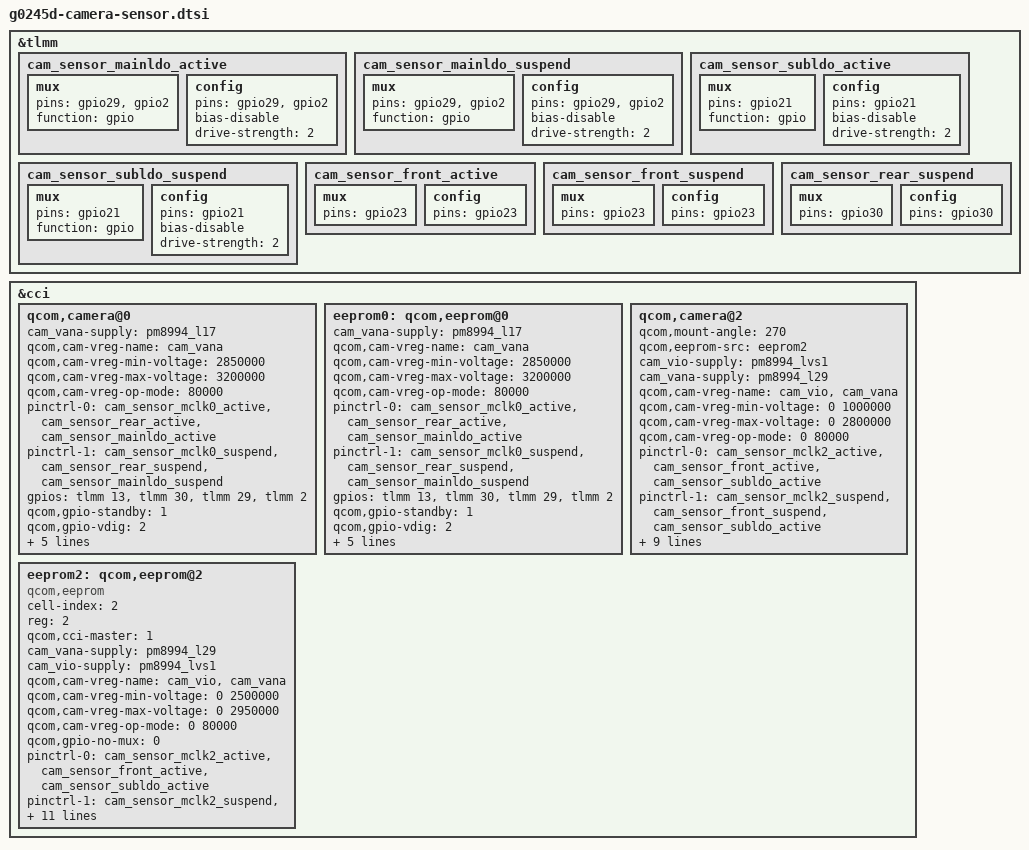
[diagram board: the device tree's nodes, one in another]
/*
 * G0245D camera sensor board topology (from the stock G0245D DTB).
 *
 * The board powers the camera modules through GPIO-switched rails, not
 * the MTP regulator set the donor msm8996-camera-sensor-mtp.dtsi uses:
 *   gpio29 = rear module main LDO enable (VDIG role)
 *   gpio2  = rear module VIO enable
 *   gpio21 = front module sub LDO enable (VDIG role)
 *
 * Sensor identity is resolved by the userspace probe path
 * (libmmcamera2_sensor_modules + /system/etc/camera/msm8996_camera.xml:
 * imx258 rear on CCI master 0, ov8856_cmb199 front on CCI master 1),
 * which drives the GPIO req-tbl and the vreg list taken verbatim from
 * the qcom,camera@N / qcom,eeprom@N nodes below. With the MTP config
 * the rails are never enabled and every CCI i2c read times out
 * (msm_cci_i2c_read rc -110), so the topology must match stock.
 *
 * Included after msm8996-camera-sensor-mtp.dtsi; nodes merge and the
 * properties here win.
 */

&tlmm {
	cam_sensor_mainldo_active: cam_sensor_mainldo_active {
		mux {
			pins = "gpio29", "gpio2";
			function = "gpio";
		};
		config {
			pins = "gpio29", "gpio2";
			bias-disable;
			drive-strength = <2>;
		};
	};

	cam_sensor_mainldo_suspend: cam_sensor_mainldo_suspend {
		mux {
			pins = "gpio29", "gpio2";
			function = "gpio";
		};
		config {
			pins = "gpio29", "gpio2";
			bias-disable;
			drive-strength = <2>;
		};
	};

	cam_sensor_subldo_active: cam_sensor_subldo_active {
		mux {
			pins = "gpio21";
			function = "gpio";
		};
		config {
			pins = "gpio21";
			bias-disable;
			drive-strength = <2>;
		};
	};

	cam_sensor_subldo_suspend: cam_sensor_subldo_suspend {
		mux {
			pins = "gpio21";
			function = "gpio";
		};
		config {
			pins = "gpio21";
			bias-disable;
			drive-strength = <2>;
		};
	};

	/* Stock groups drive only the standby pin; the donor set adds an
	 * extra gpio26 (front) / gpio29 (rear suspend) that stock does not
	 * touch. Pin lists merge by node name, so restate them here. */
	cam_sensor_front_active {
		mux {
			pins = "gpio23";
		};
		config {
			pins = "gpio23";
		};
	};

	cam_sensor_front_suspend {
		mux {
			pins = "gpio23";
		};
		config {
			pins = "gpio23";
		};
	};

	cam_sensor_rear_suspend {
		mux {
			pins = "gpio30";
		};
		config {
			pins = "gpio30";
		};
	};
};

&cci {
	/* The XML module list has no cell-index 1 camera; stock has no
	 * camera@1 / eeprom@1 either. Drop the MTP placeholders so nothing
	 * probes the wrong slot. */
	/delete-node/ qcom,camera@1;
	/delete-node/ qcom,eeprom@1;

	/* Rear: IMX258, CCI master 0, csiphy/csid 0. Vana is the only
	 * regulator; VDIG/VIO are gpio29/gpio2 via the req-tbl. */
	qcom,camera@0 {
		/delete-property/ qcom,ois-src;
		/delete-property/ cam_vdig-supply;
		/delete-property/ cam_vio-supply;
		/delete-property/ qcom,gpio-reset;
		/delete-property/ qcom,clock-rates;
		cam_vana-supply = <&pm8994_l17>;
		qcom,cam-vreg-name = "cam_vana";
		qcom,cam-vreg-min-voltage = <2850000>;
		qcom,cam-vreg-max-voltage = <3200000>;
		qcom,cam-vreg-op-mode = <80000>;
		pinctrl-0 = <&cam_sensor_mclk0_active
				&cam_sensor_rear_active
				&cam_sensor_mainldo_active>;
		pinctrl-1 = <&cam_sensor_mclk0_suspend
				&cam_sensor_rear_suspend
				&cam_sensor_mainldo_suspend>;
		gpios = <&tlmm 13 0>,
			<&tlmm 30 0>,
			<&tlmm 29 0>,
			<&tlmm 2 0>;
		qcom,gpio-standby = <1>;
		qcom,gpio-vdig = <2>;
		qcom,gpio-vio = <3>;
		qcom,gpio-req-tbl-num = <0 1 2 3>;
		qcom,gpio-req-tbl-flags = <1 0 0 0>;
		qcom,gpio-req-tbl-label = "CAMIF_MCLK0",
					  "CAM_STANDBY0",
					  "CAM_VDIG0",
					  "CAM_VIO0";
	};

	/* Rear eeprom (imx258_cmb200): same topology as the rear camera. */
	eeprom0: qcom,eeprom@0 {
		/delete-property/ cam_vdig-supply;
		/delete-property/ cam_vio-supply;
		/delete-property/ cam_vaf-supply;
		/delete-property/ qcom,gpio-reset;
		/delete-property/ qcom,clock-rates;
		cam_vana-supply = <&pm8994_l17>;
		qcom,cam-vreg-name = "cam_vana";
		qcom,cam-vreg-min-voltage = <2850000>;
		qcom,cam-vreg-max-voltage = <3200000>;
		qcom,cam-vreg-op-mode = <80000>;
		pinctrl-0 = <&cam_sensor_mclk0_active
				&cam_sensor_rear_active
				&cam_sensor_mainldo_active>;
		pinctrl-1 = <&cam_sensor_mclk0_suspend
				&cam_sensor_rear_suspend
				&cam_sensor_mainldo_suspend>;
		gpios = <&tlmm 13 0>,
			<&tlmm 30 0>,
			<&tlmm 29 0>,
			<&tlmm 2 0>;
		qcom,gpio-standby = <1>;
		qcom,gpio-vdig = <2>;
		qcom,gpio-vio = <3>;
		qcom,gpio-req-tbl-num = <0 1 2 3>;
		qcom,gpio-req-tbl-flags = <1 0 0 0>;
		qcom,gpio-req-tbl-label = "CAMIF_MCLK0",
					  "CAM_STANDBY0",
					  "CAM_VDIG0",
					  "CAM_VIO0";
	};

	/* Front: OV8856_CMB199, CCI master 1, csiphy/csid 2, no actuator.
	 * VDIG is gpio21 (sub LDO). Vana comes from pm8994_l29. */
	qcom,camera@2 {
		/delete-property/ qcom,actuator-src;
		/delete-property/ cam_vdig-supply;
		/delete-property/ qcom,gpio-reset;
		/delete-property/ qcom,clock-rates;
		qcom,mount-angle = <270>;
		qcom,eeprom-src = <&eeprom2>;
		cam_vio-supply = <&pm8994_lvs1>;
		cam_vana-supply = <&pm8994_l29>;
		qcom,cam-vreg-name = "cam_vio", "cam_vana";
		qcom,cam-vreg-min-voltage = <0 1000000>;
		qcom,cam-vreg-max-voltage = <0 2800000>;
		qcom,cam-vreg-op-mode = <0 80000>;
		pinctrl-0 = <&cam_sensor_mclk2_active
				&cam_sensor_front_active
				&cam_sensor_subldo_active>;
		pinctrl-1 = <&cam_sensor_mclk2_suspend
				&cam_sensor_front_suspend
				&cam_sensor_subldo_active>;
		gpios = <&tlmm 15 0>,
			<&tlmm 23 0>,
			<&tlmm 21 0>;
		qcom,gpio-standby = <1>;
		qcom,gpio-vdig = <2>;
		qcom,gpio-req-tbl-num = <0 1 2>;
		qcom,gpio-req-tbl-flags = <1 0 0>;
		qcom,gpio-req-tbl-label = "CAMIF_MCLK1",
					  "CAM_STANDBY1",
					  "CAM_VDIG1";
		qcom,sensor-position = <1>;
		qcom,cci-master = <1>;
	};

	/* Front eeprom (truly_cmb199), stock eeprom@2. */
	eeprom2: qcom,eeprom@2 {
		cell-index = <2>;
		reg = <2>;
		compatible = "qcom,eeprom";
		qcom,cci-master = <1>;
		cam_vana-supply = <&pm8994_l29>;
		cam_vio-supply = <&pm8994_lvs1>;
		qcom,cam-vreg-name = "cam_vio", "cam_vana";
		qcom,cam-vreg-min-voltage = <0 2500000>;
		qcom,cam-vreg-max-voltage = <0 2950000>;
		qcom,cam-vreg-op-mode = <0 80000>;
		qcom,gpio-no-mux = <0>;
		pinctrl-names = "cam_default", "cam_suspend";
		pinctrl-0 = <&cam_sensor_mclk2_active
				&cam_sensor_front_active
				&cam_sensor_subldo_active>;
		pinctrl-1 = <&cam_sensor_mclk2_suspend
				&cam_sensor_front_suspend
				&cam_sensor_subldo_active>;
		gpios = <&tlmm 15 0>,
			<&tlmm 23 0>,
			<&tlmm 21 0>;
		qcom,gpio-standby = <1>;
		qcom,gpio-vdig = <2>;
		qcom,gpio-req-tbl-num = <0 1 2>;
		qcom,gpio-req-tbl-flags = <1 0 0>;
		qcom,gpio-req-tbl-label = "CAMIF_MCLK1",
					  "CAM_STANDBY1",
					  "CAM_VDIG1";
		clocks = <&clock_mmss clk_mclk2_clk_src>,
			<&clock_mmss clk_camss_mclk2_clk>;
		clock-names = "cam_src_clk", "cam_clk";
	};
};
